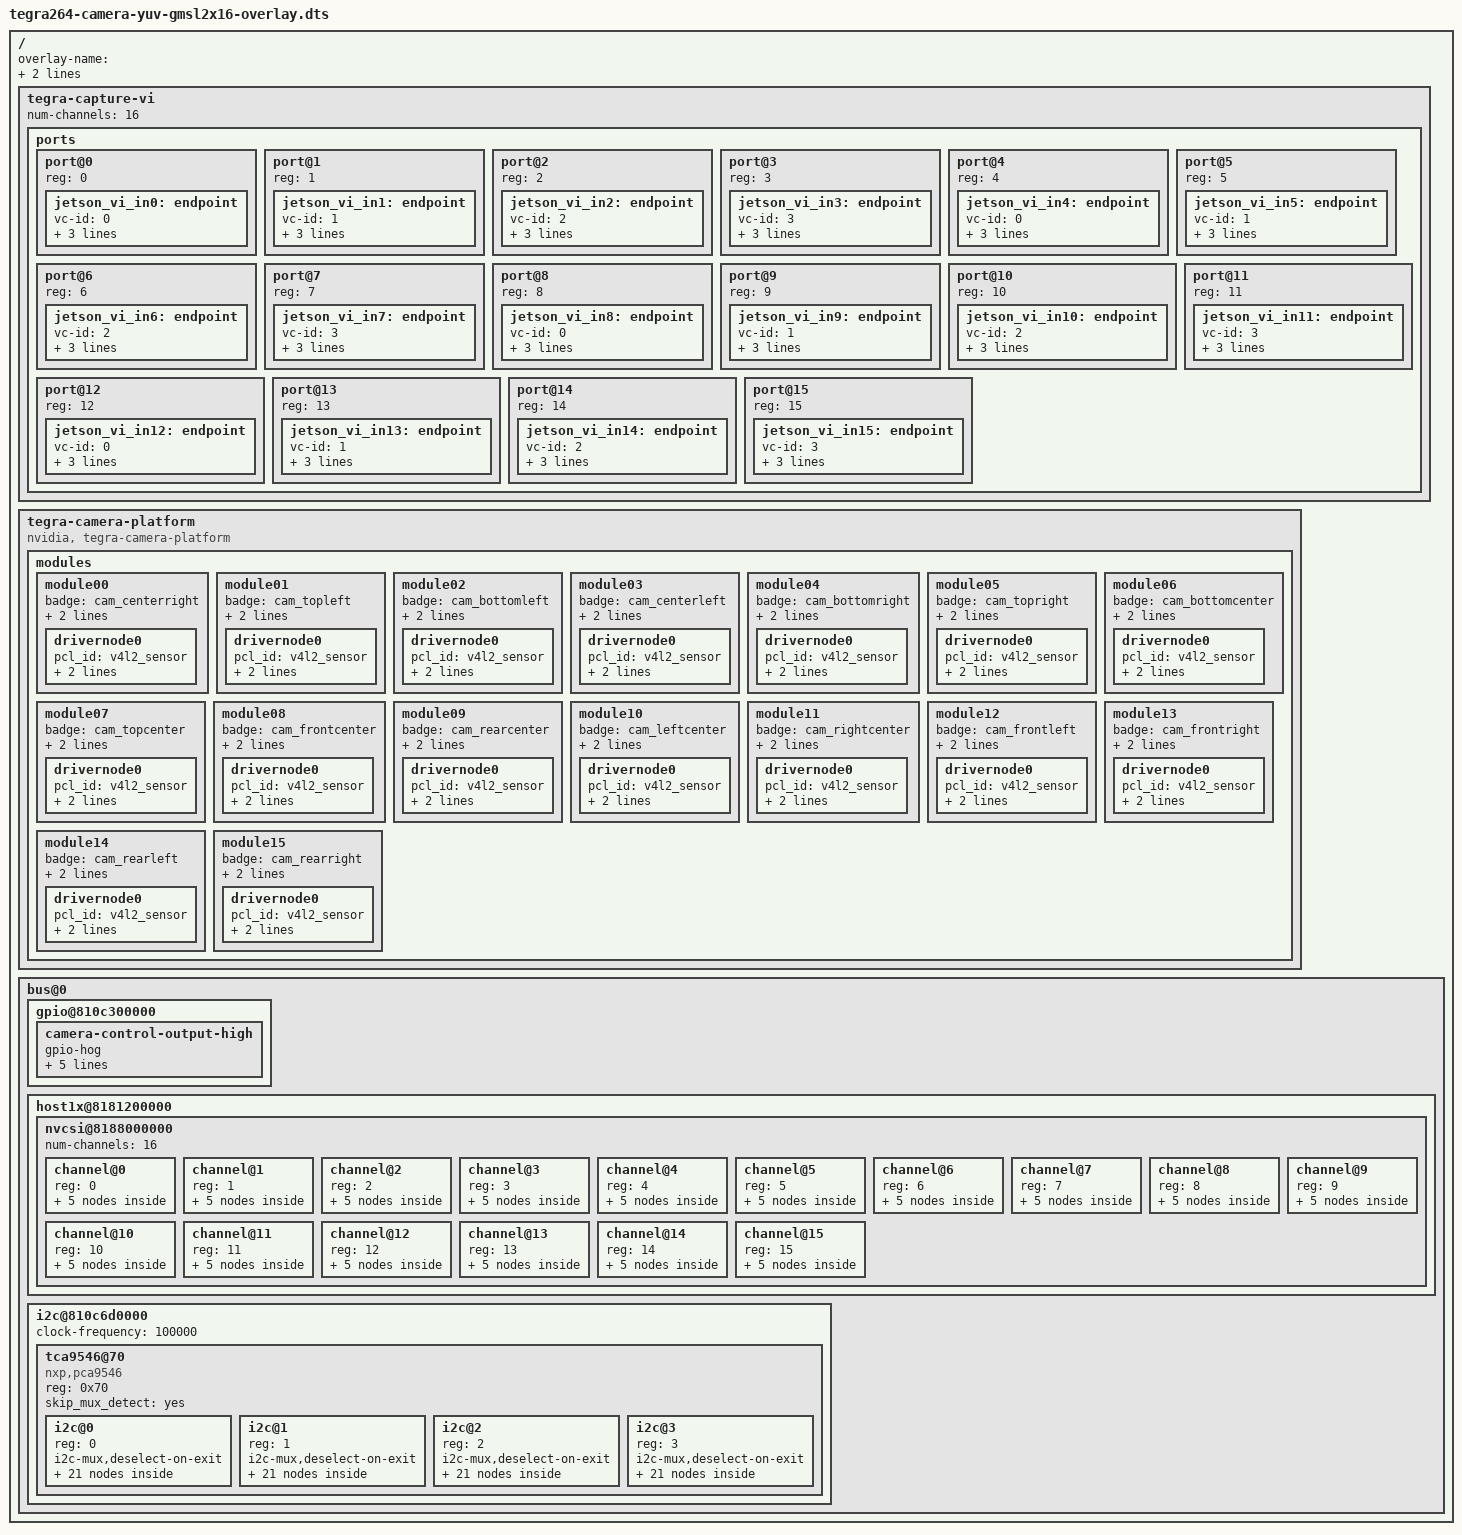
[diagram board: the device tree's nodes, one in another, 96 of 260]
// SPDX-License-Identifier: GPL-2.0-only
// SPDX-FileCopyrightText: Copyright (c) 2018-2023, INTEL CORPORATION.  All rights reserved.

/dts-v1/;
/plugin/;

#include <dt-bindings/clock/tegra264-clock.h>
#include <dt-bindings/gpio/tegra264-gpio.h>
//#include <dt-bindings/tegra234-p3737-0000+p3701-0000.h>

/* camera control gpio definitions */
#define CAM0_PWDN	TEGRA264_MAIN_GPIO(V, 1) //l49-pv01
#define CAM0_RST_L	TEGRA264_MAIN_GPIO(V, 2) //l5-pv02
#define CAM1_PWDN	TEGRA264_MAIN_GPIO(Q, 2)//f10-PQ02
#define CAM1_RST_L	TEGRA264_MAIN_GPIO(Q, 3)//f11-PQ03

// #define CAM_SYNC    TEGRA264_MAIN_GPIO(K, 5) 

// #define CAMERA_I2C_MUX_BUS(x) (0x1E + x)
#define JETSON_COMPATIBLE	"nvidia,p3971-0089+p3834-0008", "nvidia,p3971-0050+p3834-0005", "nvidia,p3971-0080+p3834-0008", "nvidia,p3834-0008", "nvidia,tegra264"

/ {
	overlay-name = "Jetson Sensing SG16A_AGTH_G3Y_A1 YUV GMSL2x16";
	jetson-header-name = "Jetson AGX CSI Connector";
	compatible = JETSON_COMPATIBLE;

	fragment@0 {
		target-path = "/";
		__overlay__ {
			tegra-capture-vi {
				num-channels = <16>;
				ports {
					status = "okay";
					port@0 {
						reg = <0>;
						status = "okay";
						jetson_vi_in0: endpoint {
							status = "okay";
							vc-id = <0>;
							port-index = <0>;
							bus-width = <4>;
							remote-endpoint = <&jetson_csi_out0>;
						};
					};
					port@1 {
						reg = <1>;
						status = "okay";
						jetson_vi_in1: endpoint {
							status = "okay";
							vc-id = <1>;
							port-index = <0>;
							bus-width = <4>;
							remote-endpoint = <&jetson_csi_out1>;
						};
					};
					port@2 {
						reg = <2>;
						status = "okay";
						jetson_vi_in2: endpoint {
							status = "okay";
							vc-id = <2>;
							port-index = <0>;
							bus-width = <4>;
							remote-endpoint = <&jetson_csi_out2>;
						};
					};
					port@3 {
						reg = <3>;
						status = "okay";
						jetson_vi_in3: endpoint {
							status = "okay";
							vc-id = <3>;
							port-index = <0>;
							bus-width = <4>;
							remote-endpoint = <&jetson_csi_out3>;
						};
					};
					port@4 {
						reg = <4>;
						status = "okay";
						jetson_vi_in4: endpoint {
							status = "okay";
							vc-id = <0>;
							port-index = <5>;
							bus-width = <4>;
							remote-endpoint = <&jetson_csi_out4>;
						};
					};
					port@5 {
						reg = <5>;
						status = "okay";
						jetson_vi_in5: endpoint {
							status = "okay";
							vc-id = <1>;
							port-index = <5>;
							bus-width = <4>;
							remote-endpoint = <&jetson_csi_out5>;
						};
					};
					port@6 {
						reg = <6>;
						status = "okay";
						jetson_vi_in6: endpoint {
							status = "okay";
							vc-id = <2>;
							port-index = <5>;
							bus-width = <4>;
							remote-endpoint = <&jetson_csi_out6>;
						};
					};
					port@7 {
						reg = <7>;
						status = "okay";
						jetson_vi_in7: endpoint {
							status = "okay";
							vc-id = <3>;
							port-index = <5>;
							bus-width = <4>;
							remote-endpoint = <&jetson_csi_out7>;
						};
					};
					port@8 {
						reg = <8>;
						status = "okay";
						jetson_vi_in8: endpoint {
							status = "okay";
							vc-id = <0>;
							port-index = <4>;
							bus-width = <4>;
							remote-endpoint = <&jetson_csi_out8>;
						};
					};
					port@9 {
						reg = <9>;
						status = "okay";
						jetson_vi_in9: endpoint {
							status = "okay";
							vc-id = <1>;
							port-index = <4>;
							bus-width = <4>;
							remote-endpoint = <&jetson_csi_out9>;
						};
					};
					port@10 {
						reg = <10>;
						status = "okay";
						jetson_vi_in10: endpoint {
							status = "okay";
							vc-id = <2>;
							port-index = <4>;
							bus-width = <4>;
							remote-endpoint = <&jetson_csi_out10>;
						};
					};
					port@11 {
						reg = <11>;
						status = "okay";
						jetson_vi_in11: endpoint {
							status = "okay";
							vc-id = <3>;
							port-index = <4>;
							bus-width = <4>;
							remote-endpoint = <&jetson_csi_out11>;
						};
					};
					port@12 {
						reg = <12>;
						status = "okay";
						jetson_vi_in12: endpoint {
							status = "okay";
							vc-id = <0>;
							port-index = <2>;
							bus-width = <4>;
							remote-endpoint = <&jetson_csi_out12>;
						};
					};
					port@13 {
						reg = <13>;
						status = "okay";
						jetson_vi_in13: endpoint {
							status = "okay";
							vc-id = <1>;
							port-index = <2>;
							bus-width = <4>;
							remote-endpoint = <&jetson_csi_out13>;
						};
					};
					port@14 {
						reg = <14>;
						status = "okay";
						jetson_vi_in14: endpoint {
							status = "okay";
							vc-id = <2>;
							port-index = <2>;
							bus-width = <4>;
							remote-endpoint = <&jetson_csi_out14>;
						};
					};
					port@15 {
						reg = <15>;
						status = "okay";
						jetson_vi_in15: endpoint {
							status = "okay";
							vc-id = <3>;
							port-index = <2>;
							bus-width = <4>;
							remote-endpoint = <&jetson_csi_out15>;
						};
					};
				};
			};
	
			tegra-camera-platform {
				compatible = "nvidia, tegra-camera-platform";

				modules {
					status = "okay";
					module00 {
						status = "okay";
						badge = "cam_centerright";
						position = "centerright";
						orientation = "1";
						drivernode0 {
							status = "okay";
							pcl_id = "v4l2_sensor";
							sysfs-device-tree = "/sys/firmware/devicetree/base/bus@0/i2c@810c6d0000/tca9546@70/i2c@0/cam_0@2a";
						};
					};
					module01 {
						status = "okay";
						badge = "cam_topleft";
						position = "topleft";
						orientation = "1";
						drivernode0 {
							status = "okay";
							pcl_id = "v4l2_sensor";
							sysfs-device-tree = "/sys/firmware/devicetree/base/bus@0/i2c@810c6d0000/tca9546@70/i2c@0/cam_1@2b";
						};
					};
					module02 {
						status = "okay";
						badge = "cam_bottomleft";
						position = "bottomleft";
						orientation = "1";
						drivernode0 {
							status = "okay";
							pcl_id = "v4l2_sensor";
							sysfs-device-tree = "/sys/firmware/devicetree/base/bus@0/i2c@810c6d0000/tca9546@70/i2c@0/cam_2@2c";
						};
					};
					module03 {
						status = "okay";
						badge = "cam_centerleft";
						position = "centerleft";
						orientation = "1";
						drivernode0 {
							status = "okay";
							pcl_id = "v4l2_sensor";
							sysfs-device-tree = "/sys/firmware/devicetree/base/bus@0/i2c@810c6d0000/tca9546@70/i2c@0/cam_3@2d";
						};
					};
					module04 {
						status = "okay";
						badge = "cam_bottomright";
						position = "bottomright";
						orientation = "1";
						drivernode0 {
							status = "okay";
							pcl_id = "v4l2_sensor";
							sysfs-device-tree = "/sys/firmware/devicetree/base/bus@0/i2c@810c6d0000/tca9546@70/i2c@1/cam_4@2a";
						};
					};
					module05 {
						status = "okay";
						badge = "cam_topright";
						position = "topright";
						orientation = "1";
						drivernode0 {
							status = "okay";
							pcl_id = "v4l2_sensor";
							sysfs-device-tree = "/sys/firmware/devicetree/base/bus@0/i2c@810c6d0000/tca9546@70/i2c@1/cam_5@2b";
						};
					};
					module06 {
						status = "okay";
						badge = "cam_bottomcenter";
						position = "bottomcenter";
						orientation = "1";
						drivernode0 {
							status = "okay";
							pcl_id = "v4l2_sensor";
							sysfs-device-tree = "/sys/firmware/devicetree/base/bus@0/i2c@810c6d0000/tca9546@70/i2c@1/cam_6@2c";
						};
					};
					module07 {
						status = "okay";
						badge = "cam_topcenter";
						position = "topcenter";
						orientation = "1";
						drivernode0 {
							status = "okay";
							pcl_id = "v4l2_sensor";
							sysfs-device-tree = "/sys/firmware/devicetree/base/bus@0/i2c@810c6d0000/tca9546@70/i2c@1/cam_7@2d";
						};
					};
					module08 {
						status = "okay";
						badge = "cam_frontcenter";
						position = "frontcenter";
						orientation = "1";
						drivernode0 {
							status = "okay";
							pcl_id = "v4l2_sensor";
							sysfs-device-tree = "/sys/firmware/devicetree/base/bus@0/i2c@810c6d0000/tca9546@70/i2c@2/cam_8@2a";
						};
					};
					module09 {
						status = "okay";
						badge = "cam_rearcenter";
						position = "rearcenter";
						orientation = "1";
						drivernode0 {
							status = "okay";
							pcl_id = "v4l2_sensor";
							sysfs-device-tree = "/sys/firmware/devicetree/base/bus@0/i2c@810c6d0000/tca9546@70/i2c@2/cam_9@2b";
						};
					};
					module10 {
						status = "okay";
						badge = "cam_leftcenter";
						position = "leftcenter";
						orientation = "1";
						drivernode0 {
							status = "okay";
							pcl_id = "v4l2_sensor";
							sysfs-device-tree = "/sys/firmware/devicetree/base/bus@0/i2c@810c6d0000/tca9546@70/i2c@2/cam_10@2c";
						};
					};
					module11 {
						status = "okay";
						badge = "cam_rightcenter";
						position = "rightcenter";
						orientation = "1";
						drivernode0 {
							status = "okay";
							pcl_id = "v4l2_sensor";
							sysfs-device-tree = "/sys/firmware/devicetree/base/bus@0/i2c@810c6d0000/tca9546@70/i2c@2/cam_11@2d";
						};
					};
					module12 {
						status = "okay";
						badge = "cam_frontleft";
						position = "frontleft";
						orientation = "1";
						drivernode0 {
							status = "okay";
							pcl_id = "v4l2_sensor";
							sysfs-device-tree = "/sys/firmware/devicetree/base/bus@0/i2c@810c6d0000/tca9546@70/i2c@3/cam_12@2a";
						};
					};
					module13 {
						status = "okay";
						badge = "cam_frontright";
						position = "frontright";
						orientation = "1";
						drivernode0 {
							status = "okay";
							pcl_id = "v4l2_sensor";
							sysfs-device-tree = "/sys/firmware/devicetree/base/bus@0/i2c@810c6d0000/tca9546@70/i2c@3/cam_13@2b";
						};
					};
					module14 {
						status = "okay";
						badge = "cam_rearleft";
						position = "rearleft";
						orientation = "1";
						drivernode0 {
							status = "okay";
							pcl_id = "v4l2_sensor";
							sysfs-device-tree = "/sys/firmware/devicetree/base/bus@0/i2c@810c6d0000/tca9546@70/i2c@3/cam_14@2c";
						};
					};
					module15 {
						status = "okay";
						badge = "cam_rearright";
						position = "rearright";
						orientation = "1";
						drivernode0 {
							status = "okay";
							pcl_id = "v4l2_sensor";
							sysfs-device-tree = "/sys/firmware/devicetree/base/bus@0/i2c@810c6d0000/tca9546@70/i2c@3/cam_15@2d";
						};
					};
				};
			};

			bus@0 {
				/* set camera gpio direction to output */
				gpio@810c300000 {
					camera-control-output-high {
						gpio-hog;
						output-high;
						gpios = <CAM0_RST_L 0 CAM0_PWDN 0 CAM1_RST_L 0 CAM1_PWDN 0>;//0：高电平有效
						label = "cam0-rst", "cam0-pwdn", "cam1-rst", "cam1-pwdn";
					};
				};
				// pwm-gpio { //TODO 修改上面的宏就行
				// 	compatible = "pwm-gpio";
				// 	status = "okay";
				// 	gpios = <&gpio_main CAM_SYNC GPIO_ACTIVE_LOW>;
				// };

				host1x@8181200000 {
					nvcsi@8188000000 {
						num-channels = <16>;
						channel@0 {
							reg = <0>;
							status = "okay";
							ports {
								status = "okay";
								port@0 {
									reg = <0>;
									status = "okay";
									jetson_csi_in0: endpoint@0 {
										status = "okay";
										port-index = <0>;
										bus-width = <4>;
										remote-endpoint = <&cam_csi_out0>;
									};
								};
								port@1 {
									reg = <1>;
									status = "okay";
									jetson_csi_out0: endpoint@1 {
										status = "okay";
										remote-endpoint = <&jetson_vi_in0>;
									};
								};
							};
						};
						channel@1 {
							reg = <1>;
							status = "okay";
							ports {
								status = "okay";
								port@0 {
									reg = <0>;
									status = "okay";
									jetson_csi_in1: endpoint@2 {
										status = "okay";
										port-index = <0>;
										bus-width = <4>;
										remote-endpoint = <&cam_csi_out1>;
									};
								};
								port@1 {
									reg = <1>;
									status = "okay";
									jetson_csi_out1: endpoint@3 {
										status = "okay";
										remote-endpoint = <&jetson_vi_in1>;
									};
								};
							};
						};
						channel@2 {
							reg = <2>;
							status = "okay";
							ports {
								status = "okay";
								port@0 {
									reg = <0>;
									status = "okay";
									jetson_csi_in2: endpoint@4 {
										status = "okay";
										port-index = <0>;
										bus-width = <4>;
										remote-endpoint = <&cam_csi_out2>;
									};
								};
								port@1 {
									reg = <1>;
									status = "okay";
									jetson_csi_out2: endpoint@5 {
										status = "okay";
										remote-endpoint = <&jetson_vi_in2>;
									};
								};
							};
						};
						channel@3 {
							reg = <3>;
							status = "okay";
							ports {
								status = "okay";
								port@0 {
									reg = <0>;
									status = "okay";
									jetson_csi_in3: endpoint@6 {
										status = "okay";
										port-index = <0>;
										bus-width = <4>;
										remote-endpoint = <&cam_csi_out3>;
									};
								};
								port@1 {
									reg = <1>;
									status = "okay";
									jetson_csi_out3: endpoint@7 {
										status = "okay";
										remote-endpoint = <&jetson_vi_in3>;
									};
								};
							};
						};
						channel@4 {
							reg = <4>;
							status = "okay";
							ports {
								status = "okay";
								port@0 {
									reg = <0>;
									status = "okay";
									jetson_csi_in4: endpoint@08{
										status = "okay";
										port-index = <6>;
										bus-width = <4>;
										remote-endpoint = <&cam_csi_out4>;
									};
								};
								port@1 {
									reg = <1>;
									status = "okay";
									jetson_csi_out4: endpoint@9 {
										status = "okay";
										remote-endpoint = <&jetson_vi_in4>;
									};
								};
							};
						};
						channel@5 {
							reg = <5>;
							status = "okay";
							ports {
								status = "okay";
								port@0 {
									reg = <0>;
									status = "okay";
									jetson_csi_in5: endpoint@10 {
										status = "okay";
										port-index = <6>;
										bus-width = <4>;
										remote-endpoint = <&cam_csi_out5>;
									};
								};
								port@1 {
									reg = <1>;
									status = "okay";
									jetson_csi_out5: endpoint@11 {
										status = "okay";
										remote-endpoint = <&jetson_vi_in5>;
									};
								};
							};
						};
						channel@6 {
							reg = <6>;
							status = "okay";
							ports {
								status = "okay";
								port@0 {
									reg = <0>;
									status = "okay";
									jetson_csi_in6: endpoint@12 {
										status = "okay";
										port-index = <6>;
										bus-width = <4>;
										remote-endpoint = <&cam_csi_out6>;
									};
								};
								port@1 {
									reg = <1>;
									status = "okay";
									jetson_csi_out6: endpoint@13 {
										status = "okay";
										remote-endpoint = <&jetson_vi_in6>;
									};
								};
							};
						};
						channel@7 {
							reg = <7>;
							status = "okay";
							ports {
								status = "okay";
								port@0 {
									reg = <0>;
									status = "okay";
									jetson_csi_in7: endpoint@14 {
										status = "okay";
										port-index = <6>;
										bus-width = <4>;
										remote-endpoint = <&cam_csi_out7>;
									};
								};
								port@1 {
									reg = <1>;
									status = "okay";
									jetson_csi_out7: endpoint@15 {
										status = "okay";
										remote-endpoint = <&jetson_vi_in7>;
									};
								};
							};
						};
						channel@8 {
							reg = <8>;
							status = "okay";
							ports {
								status = "okay";
								port@0 {
									reg = <0>;
									status = "okay";
									jetson_csi_in8: endpoint@16 {
										status = "okay";
										port-index = <4>;
										bus-width = <4>;
										remote-endpoint = <&cam_csi_out8>;
									};
								};
								port@1 {
									reg = <1>;
									status = "okay";
									jetson_csi_out8: endpoint@17 {
										status = "okay";
										remote-endpoint = <&jetson_vi_in8>;
									};
								};
							};
						};
						channel@9 {
							reg = <9>;
							status = "okay";
							ports {
								status = "okay";
								port@0 {
									reg = <0>;
									status = "okay";
									jetson_csi_in9: endpoint@18 {
										status = "okay";
										port-index = <4>;
										bus-width = <4>;
										remote-endpoint = <&cam_csi_out9>;
									};
								};
								port@1 {
									reg = <1>;
									status = "okay";
									jetson_csi_out9: endpoint@19 {
										status = "okay";
										remote-endpoint = <&jetson_vi_in9>;
									};
								};
							};
						};
						channel@10 {
							reg = <10>;
							status = "okay";
							ports {
								status = "okay";
								port@0 {
									reg = <0>;
									status = "okay";
									jetson_csi_in10: endpoint@20 {
										status = "okay";
										port-index = <4>;
										bus-width = <4>;
										remote-endpoint = <&cam_csi_out10>;
									};
								};
								port@1 {
									reg = <1>;
									status = "okay";
									jetson_csi_out10: endpoint@21 {
										status = "okay";
										remote-endpoint = <&jetson_vi_in10>;
									};
								};
							};
						};
						channel@11 {
							reg = <11>;
							status = "okay";
							ports {
								status = "okay";
								port@0 {
									reg = <0>;
									status = "okay";
									jetson_csi_in11: endpoint@22 {
										status = "okay";
										port-index = <4>;
										bus-width = <4>;
										remote-endpoint = <&cam_csi_out11>;
									};
								};
								port@1 {
									reg = <1>;
									status = "okay";
									jetson_csi_out11: endpoint@23 {
										status = "okay";
										remote-endpoint = <&jetson_vi_in11>;
									};
								};
							};
						};
						channel@12 {
							reg = <12>;
							status = "okay";
							ports {
								status = "okay";
								port@0 {
									reg = <0>;
									status = "okay";
									jetson_csi_in12: endpoint@24 {
										status = "okay";
										port-index = <2>;
										bus-width = <4>;
										remote-endpoint = <&cam_csi_out12>;
									};
								};
								port@1 {
									reg = <1>;
									status = "okay";
									jetson_csi_out12: endpoint@25 {
										status = "okay";
										remote-endpoint = <&jetson_vi_in12>;
									};
								};
							};
						};
						channel@13 {
							reg = <13>;
							status = "okay";
							ports {
								status = "okay";
								port@0 {
									reg = <0>;
									status = "okay";
									jetson_csi_in13: endpoint@26 {
										status = "okay";
										port-index = <2>;
										bus-width = <4>;
										remote-endpoint = <&cam_csi_out13>;
									};
								};
								port@1 {
									reg = <1>;
									status = "okay";
									jetson_csi_out13: endpoint@27 {
										status = "okay";
										remote-endpoint = <&jetson_vi_in13>;
									};
								};
							};
						};
						channel@14 {
							reg = <14>;
							status = "okay";
							ports {
								status = "okay";
								port@0 {
									reg = <0>;
									status = "okay";
									jetson_csi_in14: endpoint@28 {
										status = "okay";
										port-index = <2>;
										bus-width = <4>;
										remote-endpoint = <&cam_csi_out14>;
									};
								};
								port@1 {
									reg = <1>;
									status = "okay";
									jetson_csi_out14: endpoint@29 {
										status = "okay";
										remote-endpoint = <&jetson_vi_in14>;
									};
								};
							};
						};
						channel@15 {
							reg = <15>;
							status = "okay";
							ports {
								status = "okay";
								port@0 {
									reg = <0>;
									status = "okay";
									jetson_csi_in15: endpoint@30 {
										status = "okay";
										port-index = <2>;
										bus-width = <4>;
										remote-endpoint = <&cam_csi_out15>;
									};
								};
								port@1 {
									reg = <1>;
									status = "okay";
									jetson_csi_out15: endpoint@31 {
										status = "okay";
										remote-endpoint = <&jetson_vi_in15>;
									};
								};
							};
						};
					};
				};

				i2c@810c6d0000 {
					clock-frequency = <100000>;

					tca9546@70 {
						compatible = "nxp,pca9546";
						reg = <0x70>;
						#address-cells = <1>;
						#size-cells = <0>;
						skip_mux_detect = "yes";
						status = "okay";

						i2c@0 {
                            status = "okay";
							reg = <0>;
							i2c-mux,deselect-on-exit;
							#address-cells = <1>;
							#size-cells = <0>;

							max96726_0@20 {
								compatible = "nvidia,max96726_0";
								reg = <0x20>;
							};
							cam_3@2d {
								compatible = "sensing,sgx-yuv-gmsl2-3";
								def-addr = <0x1a>;
								reg = <0x2d>;
								eeprom-def = <0x50>;
								eeprom-addr = <0x63>;
								devnode = "video3";

								/* Physical dimensions of sensor */
								physical_w = "15.0";
								physical_h = "12.5";

								sensor_model ="sgx-yuv-gmsl2";

								/* Defines number of frames to be dropped by driver internally after applying */
								/* sensor crop settings. Some sensors send corrupt frames after applying */
								/* crop co-ordinates */
								post_crop_frame_drop = "0";

								/* Convert Gain to unit of dB (decibel) befor passing to kernel driver */
								use_decibel_gain = "true";

								/* enable CID_SENSOR_MODE_ID for sensor modes selection */
								use_sensor_mode_id = "true";

								clocks = <&bpmp TEGRA264_CLK_EXTPERIPH1>,
								<&bpmp TEGRA264_CLK_EXTPERIPH1>;
								clock-names = "extperiph1", "pllp_grtba";
								mclk = "extperiph1";
								der_id = <0>;
								reset-gpios = <&gpio_main CAM0_PWDN GPIO_ACTIVE_HIGH>;//TODO

								mode0 {/*mode IMX424_MODE_3840X2160_CROP_30FPS*/
									mclk_khz = "24000";
									num_lanes = "4";
									tegra_sinterface = "serial_a";
									vc_id = "3";
									phy_mode = "CPHY";
									discontinuous_clk = "no";
									dpcm_enable = "false";
									cil_settletime = "0";
									dynamic_pixel_bit_depth = "16";
									csi_pixel_bit_depth = "16";
									mode_type = "yuv";
									pixel_phase = "uyvy";

									active_w = "3840";
									active_h = "2160";
									readout_orientation = "0";
									line_length = "4200";
									inherent_gain = "1";
									pix_clk_hz = "320000000";
									serdes_pix_clk_hz = "800000000";//3200*4/16
									
									gain_factor = "100";
									min_gain_val = "100"; /* dB */
									max_gain_val = "1600"; /* dB */
									step_gain_val = "1"; /* 0.1 */
									default_gain = "100";
									min_hdr_ratio = "1";
									max_hdr_ratio = "1";
									framerate_factor = "1000000";
									min_framerate = "30000000";
									max_framerate = "30000000";
									step_framerate = "1";
									default_framerate = "30000000";
									exposure_factor = "1000000";
									min_exp_time = "28"; /*us, 2 lines*/
									max_exp_time = "22000";
									step_exp_time = "1";
									default_exp_time = "22000";/* us */
									embedded_metadata_height = "0";
								};
								ports {
									#address-cells = <1>;
									#size-cells = <0>;
									port@0 {
										reg = <0>;
										cam_csi_out3: endpoint {
											vc-id = <3>;
											port-index = <0>;
											bus-width = <4>;
											remote-endpoint = <&jetson_csi_in3>;
										};
									};
								};
							};
							cam_2@2c {
								compatible = "sensing,sgx-yuv-gmsl2-2";
								def-addr = <0x1a>;
								reg = <0x2c>;
								eeprom-def = <0x50>;
								eeprom-addr = <0x62>;
								devnode = "video2";

								/* Physical dimensions of sensor */
								physical_w = "15.0";
								physical_h = "12.5";

								sensor_model ="sgx-yuv-gmsl2";

								/* Defines number of frames to be dropped by driver internally after applying */
								/* sensor crop settings. Some sensors send corrupt frames after applying */
								/* crop co-ordinates */
								post_crop_frame_drop = "0";

								/* Convert Gain to unit of dB (decibel) befor passing to kernel driver */
								use_decibel_gain = "true";

								/* enable CID_SENSOR_MODE_ID for sensor modes selection */
								use_sensor_mode_id = "true";

								clocks = <&bpmp TEGRA264_CLK_EXTPERIPH1>,
								<&bpmp TEGRA264_CLK_EXTPERIPH1>;
								clock-names = "extperiph1", "pllp_grtba";
								mclk = "extperiph1";
								der_id = <0>;
								reset-gpios = <&gpio_main CAM0_PWDN GPIO_ACTIVE_HIGH>;//TODO

								mode0 {/*mode IMX424_MODE_3840X1080_CROP_30FPS*/
									mclk_khz = "24000";
									num_lanes = "4";
									tegra_sinterface = "serial_a";
									vc_id = "2";
									phy_mode = "CPHY";
									discontinuous_clk = "no";
									dpcm_enable = "false";
									cil_settletime = "0";
									dynamic_pixel_bit_depth = "16";
									csi_pixel_bit_depth = "16";
									mode_type = "yuv";
									pixel_phase = "uyvy";

									active_w = "3840";
									active_h = "2160";
									readout_orientation = "0";
									line_length = "4200";
									inherent_gain = "1";
									pix_clk_hz = "320000000";
									serdes_pix_clk_hz = "800000000";			//3200*4/16

									gain_factor = "100";
									min_gain_val = "100"; /* dB */
									max_gain_val = "1600"; /* dB */
									step_gain_val = "1"; /* 0.1 */
									default_gain = "100";
									min_hdr_ratio = "1";
									max_hdr_ratio = "1";
									framerate_factor = "1000000";
									min_framerate = "30000000";
									max_framerate = "30000000";
									step_framerate = "1";
									default_framerate = "30000000";
									exposure_factor = "1000000";
									min_exp_time = "28"; /*us, 2 lines*/
									max_exp_time = "22000";
									step_exp_time = "1";
									default_exp_time = "22000";/* us */
									embedded_metadata_height = "0";
								};
								ports {
									#address-cells = <1>;
									#size-cells = <0>;
									port@0 {
										reg = <0>;
										cam_csi_out2: endpoint {
											vc-id = <2>;
											port-index = <0>;
											bus-width = <4>;
											remote-endpoint = <&jetson_csi_in2>;
										};
									};
								};
							};
							cam_1@2b {
								compatible = "sensing,sgx-yuv-gmsl2-1";
								def-addr = <0x1a>;
								reg = <0x2b>;
								eeprom-def = <0x50>;
								eeprom-addr = <0x61>;
								devnode = "video1";

								/* Physical dimensions of sensor */
								physical_w = "15.0";
								physical_h = "12.5";

								sensor_model ="sgx-yuv-gmsl2";

								/* Defines number of frames to be dropped by driver internally after applying */
								/* sensor crop settings. Some sensors send corrupt frames after applying */
								/* crop co-ordinates */
								post_crop_frame_drop = "0";

								/* Convert Gain to unit of dB (decibel) befor passing to kernel driver */
								use_decibel_gain = "true";

								/* enable CID_SENSOR_MODE_ID for sensor modes selection */
								use_sensor_mode_id = "true";

								clocks = <&bpmp TEGRA264_CLK_EXTPERIPH1>,
								<&bpmp TEGRA264_CLK_EXTPERIPH1>;
								clock-names = "extperiph1", "pllp_grtba";
								mclk = "extperiph1";
								der_id = <0>;
								reset-gpios = <&gpio_main CAM0_PWDN GPIO_ACTIVE_HIGH>;//TODO

								mode0 {
									mclk_khz = "24000";
									num_lanes = "4";
									tegra_sinterface = "serial_a";
									vc_id = "1";
									phy_mode = "CPHY";
									discontinuous_clk = "no";
									dpcm_enable = "false";
									cil_settletime = "0";
									dynamic_pixel_bit_depth = "16";
									csi_pixel_bit_depth = "16";
									mode_type = "yuv";
									pixel_phase = "uyvy";

									active_w = "3840";
									active_h = "2160";
									readout_orientation = "0";
									line_length = "4200";
									inherent_gain = "1";
									pix_clk_hz = "320000000";
									serdes_pix_clk_hz = "800000000";//3200*4/16

									gain_factor = "100";
									min_gain_val = "100"; /* dB */
									max_gain_val = "1600"; /* dB */
									step_gain_val = "1"; /* 0.1 */
									default_gain = "100";
									min_hdr_ratio = "1";
									max_hdr_ratio = "1";
									framerate_factor = "1000000";
									min_framerate = "30000000";
									max_framerate = "30000000";
									step_framerate = "1";
									default_framerate = "30000000";
									exposure_factor = "1000000";
									min_exp_time = "28"; /*us, 2 lines*/
									max_exp_time = "22000";
									step_exp_time = "1";
									default_exp_time = "22000";/* us */
									embedded_metadata_height = "0";
								};
								ports {
									#address-cells = <1>;
									#size-cells = <0>;
									port@0 {
										reg = <0>;
										cam_csi_out1: endpoint {
											vc-id = <1>;
											port-index = <0>;
											bus-width = <4>;
											remote-endpoint = <&jetson_csi_in1>;
										};
									};
								};
							};
							cam_0@2a {
								compatible = "sensing,sgx-yuv-gmsl2-0";
								def-addr = <0x1a>;
								reg = <0x2a>;
								eeprom-def = <0x50>;
								eeprom-addr = <0x60>;
								devnode = "video0";

								/* Physical dimensions of sensor */
								physical_w = "15.0";
								physical_h = "12.5";

								sensor_model ="sgx-yuv-gmsl2";

								/* Defines number of frames to be dropped by driver internally after applying */
								/* sensor crop settings. Some sensors send corrupt frames after applying */
								/* crop co-ordinates */
								post_crop_frame_drop = "0";

								/* Convert Gain to unit of dB (decibel) befor passing to kernel driver */
								use_decibel_gain = "true";

								/* enable CID_SENSOR_MODE_ID for sensor modes selection */
								use_sensor_mode_id = "true";

								clocks = <&bpmp TEGRA264_CLK_EXTPERIPH1>,
								<&bpmp TEGRA264_CLK_EXTPERIPH1>;
								clock-names = "extperiph1", "pllp_grtba";
								mclk = "extperiph1";
								der_id = <0>;
								reset-gpios = <&gpio_main CAM0_PWDN GPIO_ACTIVE_HIGH>;//TODO

								mode0 {
									mclk_khz = "24000";
									num_lanes = "4";
									tegra_sinterface = "serial_a";
									vc_id = "0";
									phy_mode = "CPHY";
									discontinuous_clk = "no";
									dpcm_enable = "false";
									cil_settletime = "0";
									dynamic_pixel_bit_depth = "16";
									csi_pixel_bit_depth = "16";
									mode_type = "yuv";
									pixel_phase = "uyvy";

									active_w = "3840";
									active_h = "2160";
									readout_orientation = "0";
									line_length = "4200";
									inherent_gain = "1";
									pix_clk_hz = "320000000";
									serdes_pix_clk_hz = "800000000";//3200*4/16

									gain_factor = "100";
									min_gain_val = "100"; /* dB */
									max_gain_val = "1600"; /* dB */
									step_gain_val = "1"; /* 0.1 */
									default_gain = "100";
									min_hdr_ratio = "1";
									max_hdr_ratio = "1";
									framerate_factor = "1000000";
									min_framerate = "30000000";
									max_framerate = "30000000";
									step_framerate = "1";
									default_framerate = "30000000";
									exposure_factor = "1000000";
									min_exp_time = "28"; /*us, 2 lines*/
									max_exp_time = "22000";
									step_exp_time = "1";
									default_exp_time = "22000";/* us */
									embedded_metadata_height = "0";
								};				
								ports {
									#address-cells = <1>;
									#size-cells = <0>;
									port@0 {
										reg = <0>;
										cam_csi_out0: endpoint {
											vc-id = <0>;
											port-index = <0>;
											bus-width = <4>;
											remote-endpoint = <&jetson_csi_in0>;
										};
									};
								};
							};
						};
						i2c@1 {
                            status = "okay";
							reg = <1>;
							i2c-mux,deselect-on-exit;
							#address-cells = <1>;
							#size-cells = <0>;

							max96726_1@33 {
								compatible = "nvidia,max96726_1";
								reg = <0x20>;
							};
							cam_7@2d {
								compatible = "sensing,sgx-yuv-gmsl2-7";
								def-addr = <0x1a>;
								reg = <0x2d>;
								eeprom-def = <0x50>;
								eeprom-addr = <0x63>;
								devnode = "video7";

								/* Physical dimensions of sensor */
								physical_w = "15.0";
								physical_h = "12.5";

								sensor_model ="sgx-yuv-gmsl2";

								/* Defines number of frames to be dropped by driver internally after applying */
								/* sensor crop settings. Some sensors send corrupt frames after applying */
								/* crop co-ordinates */
								post_crop_frame_drop = "0";

								/* Convert Gain to unit of dB (decibel) befor passing to kernel driver */
								use_decibel_gain = "true";

								/* enable CID_SENSOR_MODE_ID for sensor modes selection */
								use_sensor_mode_id = "true";

								clocks = <&bpmp TEGRA264_CLK_EXTPERIPH1>,
								<&bpmp TEGRA264_CLK_EXTPERIPH1>;
								clock-names = "extperiph1", "pllp_grtba";
								mclk = "extperiph1";
								der_id = <1>;
								reset-gpios = <&gpio_main CAM0_PWDN GPIO_ACTIVE_HIGH>;

								mode0 {
									mclk_khz = "24000";
									num_lanes = "4";
									tegra_sinterface = "serial_g";
									vc_id = "3";
									phy_mode = "CPHY";
									discontinuous_clk = "no";
									dpcm_enable = "false";
									cil_settletime = "0";
									dynamic_pixel_bit_depth = "16";
									csi_pixel_bit_depth = "16";
									mode_type = "yuv";
									pixel_phase = "uyvy";

									active_w = "3840";
									active_h = "2160";
									readout_orientation = "0";
									line_length = "4200";
									inherent_gain = "1";
									pix_clk_hz = "320000000";
									serdes_pix_clk_hz = "725000000";//2900*4/16

									gain_factor = "100";
									min_gain_val = "100"; /* dB */
									max_gain_val = "1600"; /* dB */
									step_gain_val = "1"; /* 0.1 */
									default_gain = "100";
									min_hdr_ratio = "1";
									max_hdr_ratio = "1";
									framerate_factor = "1000000";
									min_framerate = "30000000";
									max_framerate = "30000000";
									step_framerate = "1";
									default_framerate = "30000000";
									exposure_factor = "1000000";
									min_exp_time = "28"; /*us, 2 lines*/
									max_exp_time = "22000";
									step_exp_time = "1";
									default_exp_time = "22000";/* us */
									embedded_metadata_height = "0";
								};
								ports {
									#address-cells = <1>;
									#size-cells = <0>;
									port@0 {
										reg = <0>;
										cam_csi_out7: endpoint {
											vc-id = <3>;
											port-index = <6>;
											bus-width = <4>;
											remote-endpoint = <&jetson_csi_in7>;
										};
									};
								};
							};
							cam_6@2c {
								compatible = "sensing,sgx-yuv-gmsl2-6";
								def-addr = <0x1a>;
								reg = <0x2c>;
								eeprom-def = <0x50>;
								eeprom-addr = <0x62>;
								devnode = "video6";

								/* Physical dimensions of sensor */
								physical_w = "15.0";
								physical_h = "12.5";

								sensor_model ="sgx-yuv-gmsl2";

								/* Defines number of frames to be dropped by driver internally after applying */
								/* sensor crop settings. Some sensors send corrupt frames after applying */
								/* crop co-ordinates */
								post_crop_frame_drop = "0";

								/* Convert Gain to unit of dB (decibel) befor passing to kernel driver */
								use_decibel_gain = "true";

								/* enable CID_SENSOR_MODE_ID for sensor modes selection */
								use_sensor_mode_id = "true";

								clocks = <&bpmp TEGRA264_CLK_EXTPERIPH1>,
								<&bpmp TEGRA264_CLK_EXTPERIPH1>;
								clock-names = "extperiph1", "pllp_grtba";
								mclk = "extperiph1";
								der_id = <1>;
								reset-gpios = <&gpio_main CAM0_PWDN GPIO_ACTIVE_HIGH>;

								mode0 {
									mclk_khz = "24000";
									num_lanes = "4";
									tegra_sinterface = "serial_g";
									vc_id = "2";
									phy_mode = "CPHY";
									discontinuous_clk = "no";
									dpcm_enable = "false";
									cil_settletime = "0";
									dynamic_pixel_bit_depth = "16";
									csi_pixel_bit_depth = "16";
									mode_type = "yuv";
									pixel_phase = "uyvy";

									active_w = "3840";
									active_h = "2160";
									readout_orientation = "0";
									line_length = "4200";
									inherent_gain = "1";
									pix_clk_hz = "320000000";
									serdes_pix_clk_hz = "725000000";//2900*4/16

									gain_factor = "100";
									min_gain_val = "100"; /* dB */
									max_gain_val = "1600"; /* dB */
									step_gain_val = "1"; /* 0.1 */
									default_gain = "100";
									min_hdr_ratio = "1";
									max_hdr_ratio = "1";
									framerate_factor = "1000000";
									min_framerate = "30000000";
									max_framerate = "30000000";
									step_framerate = "1";
									default_framerate = "30000000";
									exposure_factor = "1000000";
									min_exp_time = "28"; /*us, 2 lines*/
									max_exp_time = "22000";
									step_exp_time = "1";
									default_exp_time = "22000";/* us */
									embedded_metadata_height = "0";
								};
								ports {
									#address-cells = <1>;
									#size-cells = <0>;
									port@0 {
										reg = <0>;
										cam_csi_out6: endpoint {
											vc-id = <2>;
											port-index = <6>;
											bus-width = <4>;
											remote-endpoint = <&jetson_csi_in6>;
										};
									};
								};
							};
							cam_5@2b {
								compatible = "sensing,sgx-yuv-gmsl2-5";
								def-addr = <0x1a>;
								reg = <0x2b>;
								eeprom-def = <0x50>;
								eeprom-addr = <0x61>;
								devnode = "video5";

								/* Physical dimensions of sensor */
								physical_w = "15.0";
								physical_h = "12.5";

								sensor_model ="sgx-yuv-gmsl2";

								/* Defines number of frames to be dropped by driver internally after applying */
								/* sensor crop settings. Some sensors send corrupt frames after applying */
								/* crop co-ordinates */
								post_crop_frame_drop = "0";

								/* Convert Gain to unit of dB (decibel) befor passing to kernel driver */
								use_decibel_gain = "true";

								/* enable CID_SENSOR_MODE_ID for sensor modes selection */
								use_sensor_mode_id = "true";

								clocks = <&bpmp TEGRA264_CLK_EXTPERIPH1>,
								<&bpmp TEGRA264_CLK_EXTPERIPH1>;
								clock-names = "extperiph1", "pllp_grtba";
								mclk = "extperiph1";
								der_id = <1>;
								reset-gpios = <&gpio_main CAM0_PWDN GPIO_ACTIVE_HIGH>;

								mode0 {
									mclk_khz = "24000";
									num_lanes = "4";
									tegra_sinterface = "serial_g";
									vc_id = "1";
									phy_mode = "CPHY";
									discontinuous_clk = "no";
									dpcm_enable = "false";
									cil_settletime = "0";
									dynamic_pixel_bit_depth = "16";
									csi_pixel_bit_depth = "16";
									mode_type = "yuv";
									pixel_phase = "uyvy";

									active_w = "3840";
									active_h = "2160";
									readout_orientation = "0";
									line_length = "4200";
									inherent_gain = "1";
									pix_clk_hz = "320000000";
									serdes_pix_clk_hz = "725000000";//2900*4/16

									gain_factor = "100";
									min_gain_val = "100"; /* dB */
									max_gain_val = "1600"; /* dB */
									step_gain_val = "1"; /* 0.1 */
									default_gain = "100";
									min_hdr_ratio = "1";
									max_hdr_ratio = "1";
									framerate_factor = "1000000";
									min_framerate = "30000000";
									max_framerate = "30000000";
									step_framerate = "1";
									default_framerate = "30000000";
									exposure_factor = "1000000";
									min_exp_time = "28"; /*us, 2 lines*/
									max_exp_time = "22000";
									step_exp_time = "1";
									default_exp_time = "22000";/* us */
									embedded_metadata_height = "0";
								};
								ports {
									#address-cells = <1>;
									#size-cells = <0>;
									port@0 {
										reg = <0>;
										cam_csi_out5: endpoint {
											vc-id = <1>;
											port-index = <6>;
											bus-width = <4>;
											remote-endpoint = <&jetson_csi_in5>;
										};
									};
								};
							};
							cam_4@2a {
								compatible = "sensing,sgx-yuv-gmsl2-4";
								def-addr = <0x1a>;
								reg = <0x2a>;
								eeprom-def = <0x50>;
								eeprom-addr = <0x60>;
								devnode = "video4";

								/* Physical dimensions of sensor */
								physical_w = "15.0";
								physical_h = "12.5";

								sensor_model ="sgx-yuv-gmsl2";

								/* Defines number of frames to be dropped by driver internally after applying */
								/* sensor crop settings. Some sensors send corrupt frames after applying */
								/* crop co-ordinates */
								post_crop_frame_drop = "0";

								/* Convert Gain to unit of dB (decibel) befor passing to kernel driver */
								use_decibel_gain = "true";

								/* enable CID_SENSOR_MODE_ID for sensor modes selection */
								use_sensor_mode_id = "true";

								clocks = <&bpmp TEGRA264_CLK_EXTPERIPH1>,
								<&bpmp TEGRA264_CLK_EXTPERIPH1>;
								clock-names = "extperiph1", "pllp_grtba";
								mclk = "extperiph1";
								der_id = <1>;
								reset-gpios = <&gpio_main CAM0_PWDN GPIO_ACTIVE_HIGH>;

								mode0 {
									mclk_khz = "24000";
									num_lanes = "4";
									tegra_sinterface = "serial_g";
									vc_id = "0";
									phy_mode = "CPHY";
									discontinuous_clk = "no";
									dpcm_enable = "false";
									cil_settletime = "0";
									dynamic_pixel_bit_depth = "16";
									csi_pixel_bit_depth = "16";
									mode_type = "yuv";
									pixel_phase = "uyvy";

									active_w = "3840";
									active_h = "2160";
									readout_orientation = "0";
									line_length = "4200";
									inherent_gain = "1";
									pix_clk_hz = "320000000";
									serdes_pix_clk_hz = "725000000";//2900*4/16

									gain_factor = "100";
									min_gain_val = "100"; /* dB */
									max_gain_val = "1600"; /* dB */
									step_gain_val = "1"; /* 0.1 */
									default_gain = "100";
									min_hdr_ratio = "1";
									max_hdr_ratio = "1";
									framerate_factor = "1000000";
									min_framerate = "30000000";
									max_framerate = "30000000";
									step_framerate = "1";
									default_framerate = "30000000";
									exposure_factor = "1000000";
									min_exp_time = "28"; /*us, 2 lines*/
									max_exp_time = "22000";
									step_exp_time = "1";
									default_exp_time = "22000";/* us */
									embedded_metadata_height = "0";
								};
								ports {
									#address-cells = <1>;
									#size-cells = <0>;
									port@0 {
										reg = <0>;
										cam_csi_out4: endpoint {
											vc-id = <0>;
											port-index = <6>;
											bus-width = <4>;
											remote-endpoint = <&jetson_csi_in4>;
										};
									};
								};
							};
						};
						i2c@2 {
                            status = "okay";
							reg = <2>;
							i2c-mux,deselect-on-exit;
							#address-cells = <1>;
							#size-cells = <0>;
							
							max96726_2@33 {
								compatible = "nvidia,max96726_2";
								reg = <0x20>;
							};
							cam_11@2d {
								compatible = "sensing,sgx-yuv-gmsl2-11";
								def-addr = <0x1a>;
								reg = <0x2d>;
								eeprom-def = <0x50>;
								eeprom-addr = <0x63>;
								devnode = "video11";

								/* Physical dimensions of sensor */
								physical_w = "15.0";
								physical_h = "12.5";

								sensor_model ="sgx-yuv-gmsl2";

								/* Defines number of frames to be dropped by driver internally after applying */
								/* sensor crop settings. Some sensors send corrupt frames after applying */
								/* crop co-ordinates */
								post_crop_frame_drop = "0";

								/* Convert Gain to unit of dB (decibel) befor passing to kernel driver */
								use_decibel_gain = "true";

								/* enable CID_SENSOR_MODE_ID for sensor modes selection */
								use_sensor_mode_id = "true";

								clocks = <&bpmp TEGRA264_CLK_EXTPERIPH1>,
								<&bpmp TEGRA264_CLK_EXTPERIPH1>;
								clock-names = "extperiph1", "pllp_grtba";
								mclk = "extperiph1";
								der_id = <2>;//
								reset-gpios = <&gpio_main CAM0_PWDN GPIO_ACTIVE_HIGH>;

								mode0 {
									mclk_khz = "24000";
									num_lanes = "4";
									tegra_sinterface = "serial_e";
									vc_id = "3";
									phy_mode = "CPHY";
									discontinuous_clk = "no";
									dpcm_enable = "false";
									cil_settletime = "0";
									dynamic_pixel_bit_depth = "16";
									csi_pixel_bit_depth = "16";
									mode_type = "yuv";
									pixel_phase = "uyvy";

									active_w = "3840";
									active_h = "2160";
									readout_orientation = "0";
									line_length = "4200";
									inherent_gain = "1";
									pix_clk_hz = "320000000";
									serdes_pix_clk_hz = "850000000";//3400*4/16

									gain_factor = "100";
									min_gain_val = "100"; /* dB */
									max_gain_val = "1600"; /* dB */
									step_gain_val = "1"; /* 0.1 */
									default_gain = "100";
									min_hdr_ratio = "1";
									max_hdr_ratio = "1";
									framerate_factor = "1000000";
									min_framerate = "30000000";
									max_framerate = "30000000";
									step_framerate = "1";
									default_framerate = "30000000";
									exposure_factor = "1000000";
									min_exp_time = "28"; /*us, 2 lines*/
									max_exp_time = "22000";
									step_exp_time = "1";
									default_exp_time = "22000";/* us */
									embedded_metadata_height = "0";
								};
								ports {
									#address-cells = <1>;
									#size-cells = <0>;
									port@0 {
										reg = <0>;
										cam_csi_out11: endpoint {
											vc-id = <3>;
											port-index = <4>;
											bus-width = <4>;
											remote-endpoint = <&jetson_csi_in11>;
										};
									};
								};
							};
							cam_10@2c {
								compatible = "sensing,sgx-yuv-gmsl2-10";
								def-addr = <0x1a>;
								reg = <0x2c>;
								eeprom-def = <0x50>;
								eeprom-addr = <0x62>;
								devnode = "video10";

								/* Physical dimensions of sensor */
								physical_w = "15.0";
								physical_h = "12.5";

								sensor_model ="sgx-yuv-gmsl2";

								/* Defines number of frames to be dropped by driver internally after applying */
								/* sensor crop settings. Some sensors send corrupt frames after applying */
								/* crop co-ordinates */
								post_crop_frame_drop = "0";

								/* Convert Gain to unit of dB (decibel) befor passing to kernel driver */
								use_decibel_gain = "true";

								/* enable CID_SENSOR_MODE_ID for sensor modes selection */
								use_sensor_mode_id = "true";

								clocks = <&bpmp TEGRA264_CLK_EXTPERIPH1>,
								<&bpmp TEGRA264_CLK_EXTPERIPH1>;
								clock-names = "extperiph1", "pllp_grtba";
								mclk = "extperiph1";
								der_id = <2>;//
								reset-gpios = <&gpio_main CAM0_PWDN GPIO_ACTIVE_HIGH>;

								mode0 {
									mclk_khz = "24000";
									num_lanes = "4";
									tegra_sinterface = "serial_e";
									vc_id = "2";
									phy_mode = "CPHY";
									discontinuous_clk = "no";
									dpcm_enable = "false";
									cil_settletime = "0";
									dynamic_pixel_bit_depth = "16";
									csi_pixel_bit_depth = "16";
									mode_type = "yuv";
									pixel_phase = "uyvy";

									active_w = "3840";
									active_h = "2160";
									readout_orientation = "0";
									line_length = "4200";
									inherent_gain = "1";
									pix_clk_hz = "320000000";
									serdes_pix_clk_hz = "850000000";//3400*4/16

									gain_factor = "100";
									min_gain_val = "100"; /* dB */
									max_gain_val = "1600"; /* dB */
									step_gain_val = "1"; /* 0.1 */
									default_gain = "100";
									min_hdr_ratio = "1";
									max_hdr_ratio = "1";
									framerate_factor = "1000000";
									min_framerate = "30000000";
									max_framerate = "30000000";
									step_framerate = "1";
									default_framerate = "30000000";
									exposure_factor = "1000000";
									min_exp_time = "28"; /*us, 2 lines*/
									max_exp_time = "22000";
									step_exp_time = "1";
									default_exp_time = "22000";/* us */
									embedded_metadata_height = "0";
								};
								ports {
									#address-cells = <1>;
									#size-cells = <0>;
									port@0 {
										reg = <0>;
										cam_csi_out10: endpoint {
											vc-id = <2>;
											port-index = <4>;
											bus-width = <4>;
											remote-endpoint = <&jetson_csi_in10>;
										};
									};
								};
							};
							cam_9@2b {
								compatible = "sensing,sgx-yuv-gmsl2-9";
								def-addr = <0x1a>;
								reg = <0x2b>;
								eeprom-def = <0x50>;
								eeprom-addr = <0x61>;
								devnode = "video9";

								/* Physical dimensions of sensor */
								physical_w = "15.0";
								physical_h = "12.5";

								sensor_model ="sgx-yuv-gmsl2";

								/* Defines number of frames to be dropped by driver internally after applying */
								/* sensor crop settings. Some sensors send corrupt frames after applying */
								/* crop co-ordinates */
								post_crop_frame_drop = "0";

								/* Convert Gain to unit of dB (decibel) befor passing to kernel driver */
								use_decibel_gain = "true";

								/* enable CID_SENSOR_MODE_ID for sensor modes selection */
								use_sensor_mode_id = "true";

								clocks = <&bpmp TEGRA264_CLK_EXTPERIPH1>,
								<&bpmp TEGRA264_CLK_EXTPERIPH1>;
								clock-names = "extperiph1", "pllp_grtba";
								mclk = "extperiph1";
								der_id = <2>;
								reset-gpios = <&gpio_main CAM0_PWDN GPIO_ACTIVE_HIGH>;

								mode0 {
									mclk_khz = "24000";
									num_lanes = "4";
									tegra_sinterface = "serial_e";
									vc_id = "1";
									phy_mode = "CPHY";
									discontinuous_clk = "no";
									dpcm_enable = "false";
									cil_settletime = "0";
									dynamic_pixel_bit_depth = "16";
									csi_pixel_bit_depth = "16";
									mode_type = "yuv";
									pixel_phase = "uyvy";

									active_w = "3840";
									active_h = "2160";
									readout_orientation = "0";
									line_length = "4200";
									inherent_gain = "1";
									pix_clk_hz = "320000000";
									serdes_pix_clk_hz = "850000000";//3400*4/16

									gain_factor = "100";
									min_gain_val = "100"; /* dB */
									max_gain_val = "1600"; /* dB */
									step_gain_val = "1"; /* 0.1 */
									default_gain = "100";
									min_hdr_ratio = "1";
									max_hdr_ratio = "1";
									framerate_factor = "1000000";
									min_framerate = "30000000";
									max_framerate = "30000000";
									step_framerate = "1";
									default_framerate = "30000000";
									exposure_factor = "1000000";
									min_exp_time = "28"; /*us, 2 lines*/
									max_exp_time = "22000";
									step_exp_time = "1";
									default_exp_time = "22000";/* us */
									embedded_metadata_height = "0";
								};
								ports {
									#address-cells = <1>;
									#size-cells = <0>;
									port@0 {
										reg = <0>;
										cam_csi_out9: endpoint {
											vc-id = <1>;
											port-index = <4>;
											bus-width = <4>;
											remote-endpoint = <&jetson_csi_in9>;
										};
									};
								};
							};
							cam_8@2a {
								compatible = "sensing,sgx-yuv-gmsl2-8";
								def-addr = <0x1a>;
								reg = <0x2a>;
								eeprom-def = <0x50>;
								eeprom-addr = <0x60>;
								devnode = "video8";

								/* Physical dimensions of sensor */
								physical_w = "15.0";
								physical_h = "12.5";

								sensor_model ="sgx-yuv-gmsl2";

								/* Defines number of frames to be dropped by driver internally after applying */
								/* sensor crop settings. Some sensors send corrupt frames after applying */
								/* crop co-ordinates */
								post_crop_frame_drop = "0";

								/* Convert Gain to unit of dB (decibel) befor passing to kernel driver */
								use_decibel_gain = "true";

								/* enable CID_SENSOR_MODE_ID for sensor modes selection */
								use_sensor_mode_id = "true";

								clocks = <&bpmp TEGRA264_CLK_EXTPERIPH1>,
								<&bpmp TEGRA264_CLK_EXTPERIPH1>;
								clock-names = "extperiph1", "pllp_grtba";
								mclk = "extperiph1";
								der_id = <2>;
								reset-gpios = <&gpio_main CAM0_PWDN GPIO_ACTIVE_HIGH>;

								mode0 {
									mclk_khz = "24000";
									num_lanes = "4";
									tegra_sinterface = "serial_e";
									vc_id = "0";
									phy_mode = "CPHY";
									discontinuous_clk = "no";
									dpcm_enable = "false";
									cil_settletime = "0";
									dynamic_pixel_bit_depth = "16";
									csi_pixel_bit_depth = "16";
									mode_type = "yuv";
									pixel_phase = "uyvy";

									active_w = "3840";
									active_h = "2160";
									readout_orientation = "0";
									line_length = "4200";
									inherent_gain = "1";
									pix_clk_hz = "320000000";
									serdes_pix_clk_hz = "850000000";//3400*4/16

									gain_factor = "100";
									min_gain_val = "100"; /* dB */
									max_gain_val = "1600"; /* dB */
									step_gain_val = "1"; /* 0.1 */
									default_gain = "100";
									min_hdr_ratio = "1";
									max_hdr_ratio = "1";
									framerate_factor = "1000000";
									min_framerate = "30000000";
									max_framerate = "30000000";
									step_framerate = "1";
									default_framerate = "30000000";
									exposure_factor = "1000000";
									min_exp_time = "28"; /*us, 2 lines*/
									max_exp_time = "22000";
									step_exp_time = "1";
									default_exp_time = "22000";/* us */
									embedded_metadata_height = "0";
								};
								ports {
									#address-cells = <1>;
									#size-cells = <0>;
									port@0 {
										reg = <0>;
										cam_csi_out8: endpoint {
											vc-id = <0>;
											port-index = <4>;
											bus-width = <4>;
											remote-endpoint = <&jetson_csi_in8>;
										};
									};
								};
							};
						};
						i2c@3 {
                            status = "okay";
							reg = <3>;
							i2c-mux,deselect-on-exit;
							#address-cells = <1>;
							#size-cells = <0>;

							max96726_3@33 {
								compatible = "nvidia,max96726_3";
								reg = <0x20>;
							};
							cam_15@2d {
								compatible = "sensing,sgx-yuv-gmsl2-15";
								def-addr = <0x1a>;
								reg = <0x2d>;
								eeprom-def = <0x50>;
								eeprom-addr = <0x63>;
								devnode = "video15";

								/* Physical dimensions of sensor */
								physical_w = "15.0";
								physical_h = "12.5";

								sensor_model ="sgx-yuv-gmsl2";

								/* Defines number of frames to be dropped by driver internally after applying */
								/* sensor crop settings. Some sensors send corrupt frames after applying */
								/* crop co-ordinates */
								post_crop_frame_drop = "0";

								/* Convert Gain to unit of dB (decibel) befor passing to kernel driver */
								use_decibel_gain = "true";

								/* enable CID_SENSOR_MODE_ID for sensor modes selection */
								use_sensor_mode_id = "true";

								clocks = <&bpmp TEGRA264_CLK_EXTPERIPH1>,
								<&bpmp TEGRA264_CLK_EXTPERIPH1>;
								clock-names = "extperiph1", "pllp_grtba";
								mclk = "extperiph1";
								der_id = <3>;//
								reset-gpios = <&gpio_main CAM0_PWDN GPIO_ACTIVE_HIGH>;

								mode0 {
									mclk_khz = "24000";
									num_lanes = "4";
									tegra_sinterface = "serial_c";
									vc_id = "3";
									phy_mode = "CPHY";
									discontinuous_clk = "no";
									dpcm_enable = "false";
									cil_settletime = "0";
									dynamic_pixel_bit_depth = "16";
									csi_pixel_bit_depth = "16";
									mode_type = "yuv";
									pixel_phase = "uyvy";

									active_w = "3840";
									active_h = "2160";
									readout_orientation = "0";
									line_length = "4200";
									inherent_gain = "1";
									pix_clk_hz = "320000000";
									serdes_pix_clk_hz = "800000000";//2900*4/16

									gain_factor = "100";
									min_gain_val = "100"; /* dB */
									max_gain_val = "1600"; /* dB */
									step_gain_val = "1"; /* 0.1 */
									default_gain = "100";
									min_hdr_ratio = "1";
									max_hdr_ratio = "1";
									framerate_factor = "1000000";
									min_framerate = "30000000";
									max_framerate = "30000000";
									step_framerate = "1";
									default_framerate = "30000000";
									exposure_factor = "1000000";
									min_exp_time = "28"; /*us, 2 lines*/
									max_exp_time = "22000";
									step_exp_time = "1";
									default_exp_time = "22000";/* us */
									embedded_metadata_height = "0";
								};
								ports {
									#address-cells = <1>;
									#size-cells = <0>;
									port@0 {
										reg = <0>;
										cam_csi_out15: endpoint {
											vc-id = <3>;
											port-index = <2>;
											bus-width = <4>;
											remote-endpoint = <&jetson_csi_in15>;
										};
									};
								};
							};
							cam_14@2c {
								compatible = "sensing,sgx-yuv-gmsl2-14";
								def-addr = <0x1a>;
								reg = <0x2c>;
								eeprom-def = <0x50>;
								eeprom-addr = <0x62>;
								devnode = "video14";

								/* Physical dimensions of sensor */
								physical_w = "15.0";
								physical_h = "12.5";

								sensor_model ="sgx-yuv-gmsl2";

								/* Defines number of frames to be dropped by driver internally after applying */
								/* sensor crop settings. Some sensors send corrupt frames after applying */
								/* crop co-ordinates */
								post_crop_frame_drop = "0";

								/* Convert Gain to unit of dB (decibel) befor passing to kernel driver */
								use_decibel_gain = "true";

								/* enable CID_SENSOR_MODE_ID for sensor modes selection */
								use_sensor_mode_id = "true";

								clocks = <&bpmp TEGRA264_CLK_EXTPERIPH1>,
								<&bpmp TEGRA264_CLK_EXTPERIPH1>;
								clock-names = "extperiph1", "pllp_grtba";
								mclk = "extperiph1";
								der_id = <3>;//
								reset-gpios = <&gpio_main CAM0_PWDN GPIO_ACTIVE_HIGH>;

								mode0 {
									mclk_khz = "24000";
									num_lanes = "4";
									tegra_sinterface = "serial_c";
									vc_id = "2";
									phy_mode = "CPHY";
									discontinuous_clk = "no";
									dpcm_enable = "false";
									cil_settletime = "0";
									dynamic_pixel_bit_depth = "16";
									csi_pixel_bit_depth = "16";
									mode_type = "yuv";
									pixel_phase = "uyvy";

									active_w = "3840";
									active_h = "2160";
									readout_orientation = "0";
									line_length = "4200";
									inherent_gain = "1";
									pix_clk_hz = "320000000";
									serdes_pix_clk_hz = "800000000";//2900*4/16

									gain_factor = "100";
									min_gain_val = "100"; /* dB */
									max_gain_val = "1600"; /* dB */
									step_gain_val = "1"; /* 0.1 */
									default_gain = "100";
									min_hdr_ratio = "1";
									max_hdr_ratio = "1";
									framerate_factor = "1000000";
									min_framerate = "30000000";
									max_framerate = "30000000";
									step_framerate = "1";
									default_framerate = "30000000";
									exposure_factor = "1000000";
									min_exp_time = "28"; /*us, 2 lines*/
									max_exp_time = "22000";
									step_exp_time = "1";
									default_exp_time = "22000";/* us */
									embedded_metadata_height = "0";
								};
								ports {
									#address-cells = <1>;
									#size-cells = <0>;
									port@0 {
										reg = <0>;
										cam_csi_out14: endpoint {
											vc-id = <2>;
											port-index = <2>;
											bus-width = <4>;
											remote-endpoint = <&jetson_csi_in14>;
										};
									};
								};
							};
							cam_13@2b {
								compatible = "sensing,sgx-yuv-gmsl2-13";
								def-addr = <0x1a>;
								reg = <0x2b>;
								eeprom-def = <0x50>;
								eeprom-addr = <0x61>;
								devnode = "video13";

								/* Physical dimensions of sensor */
								physical_w = "15.0";
								physical_h = "12.5";

								sensor_model ="sgx-yuv-gmsl2";

								/* Defines number of frames to be dropped by driver internally after applying */
								/* sensor crop settings. Some sensors send corrupt frames after applying */
								/* crop co-ordinates */
								post_crop_frame_drop = "0";

								/* Convert Gain to unit of dB (decibel) befor passing to kernel driver */
								use_decibel_gain = "true";

								/* enable CID_SENSOR_MODE_ID for sensor modes selection */
								use_sensor_mode_id = "true";

								clocks = <&bpmp TEGRA264_CLK_EXTPERIPH1>,
								<&bpmp TEGRA264_CLK_EXTPERIPH1>;
								clock-names = "extperiph1", "pllp_grtba";
								mclk = "extperiph1";
								der_id = <3>;//
								reset-gpios = <&gpio_main CAM0_PWDN GPIO_ACTIVE_HIGH>;

								mode0 {
									mclk_khz = "24000";
									num_lanes = "4";
									tegra_sinterface = "serial_c";
									vc_id = "1";
									phy_mode = "CPHY";
									discontinuous_clk = "no";
									dpcm_enable = "false";
									cil_settletime = "0";
									dynamic_pixel_bit_depth = "16";
									csi_pixel_bit_depth = "16";
									mode_type = "yuv";
									pixel_phase = "uyvy";

									active_w = "3840";
									active_h = "2160";
									readout_orientation = "0";
									line_length = "4200";
									inherent_gain = "1";
									pix_clk_hz = "320000000";
									serdes_pix_clk_hz = "800000000";//2900*4/16

									gain_factor = "100";
									min_gain_val = "100"; /* dB */
									max_gain_val = "1600"; /* dB */
									step_gain_val = "1"; /* 0.1 */
									default_gain = "100";
									min_hdr_ratio = "1";
									max_hdr_ratio = "1";
									framerate_factor = "1000000";
									min_framerate = "30000000";
									max_framerate = "30000000";
									step_framerate = "1";
									default_framerate = "30000000";
									exposure_factor = "1000000";
									min_exp_time = "28"; /*us, 2 lines*/
									max_exp_time = "22000";
									step_exp_time = "1";
									default_exp_time = "22000";/* us */
									embedded_metadata_height = "0";
								};
								ports {
									#address-cells = <1>;
									#size-cells = <0>;
									port@0 {
										reg = <0>;
										cam_csi_out13: endpoint {
											vc-id = <1>;
											port-index = <2>;
											bus-width = <4>;
											remote-endpoint = <&jetson_csi_in13>;
										};
									};
								};
							};
							cam_12@2a {
								compatible = "sensing,sgx-yuv-gmsl2-12";
								def-addr = <0x1a>;
								reg = <0x2a>;
								eeprom-def = <0x50>;
								eeprom-addr = <0x60>;
								devnode = "video12";

								/* Physical dimensions of sensor */
								physical_w = "15.0";
								physical_h = "12.5";

								sensor_model ="sgx-yuv-gmsl2";

								/* Defines number of frames to be dropped by driver internally after applying */
								/* sensor crop settings. Some sensors send corrupt frames after applying */
								/* crop co-ordinates */
								post_crop_frame_drop = "0";

								/* Convert Gain to unit of dB (decibel) befor passing to kernel driver */
								use_decibel_gain = "true";

								/* enable CID_SENSOR_MODE_ID for sensor modes selection */
								use_sensor_mode_id = "true";

								clocks = <&bpmp TEGRA264_CLK_EXTPERIPH1>,
								<&bpmp TEGRA264_CLK_EXTPERIPH1>;
								clock-names = "extperiph1", "pllp_grtba";
								mclk = "extperiph1";
								der_id = <3>;//
								reset-gpios = <&gpio_main CAM0_PWDN GPIO_ACTIVE_HIGH>;

								mode0 {
									mclk_khz = "24000";
									num_lanes = "4";
									tegra_sinterface = "serial_c";
									vc_id = "0";
									phy_mode = "CPHY";
									discontinuous_clk = "no";
									dpcm_enable = "false";
									cil_settletime = "0";
									dynamic_pixel_bit_depth = "16";
									csi_pixel_bit_depth = "16";
									mode_type = "yuv";
									pixel_phase = "uyvy";

									active_w = "3840";
									active_h = "2160";
									readout_orientation = "0";
									line_length = "4200";
									inherent_gain = "1";
									pix_clk_hz = "320000000";
									serdes_pix_clk_hz = "800000000";//2900*4/16

									gain_factor = "100";
									min_gain_val = "100"; /* dB */
									max_gain_val = "1600"; /* dB */
									step_gain_val = "1"; /* 0.1 */
									default_gain = "100";
									min_hdr_ratio = "1";
									max_hdr_ratio = "1";
									framerate_factor = "1000000";
									min_framerate = "30000000";
									max_framerate = "30000000";
									step_framerate = "1";
									default_framerate = "30000000";
									exposure_factor = "1000000";
									min_exp_time = "28"; /*us, 2 lines*/
									max_exp_time = "22000";
									step_exp_time = "1";
									default_exp_time = "22000";/* us */
									embedded_metadata_height = "0";
								};
								ports {
									#address-cells = <1>;
									#size-cells = <0>;
									port@0 {
										reg = <0>;
										cam_csi_out12: endpoint {
											vc-id = <0>;
											port-index = <2>;
											bus-width = <4>;
											remote-endpoint = <&jetson_csi_in12>;
										};
									};
								};
							};
						};
					};
				};
			};
		};
	};
};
